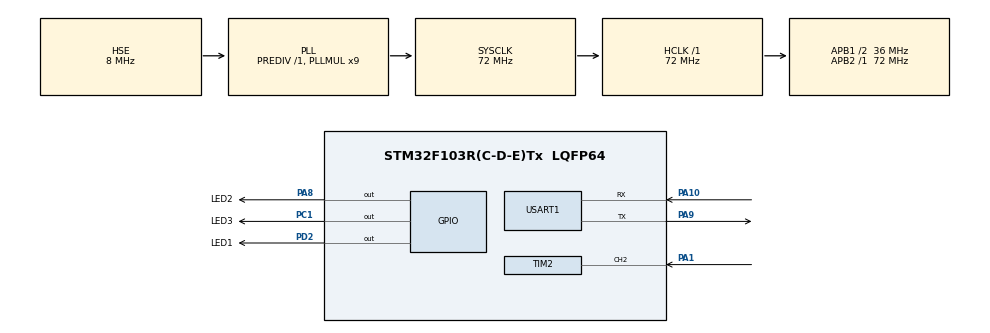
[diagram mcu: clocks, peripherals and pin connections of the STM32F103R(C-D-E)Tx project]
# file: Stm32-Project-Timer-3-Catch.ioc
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Mcu.Family=STM32F1
Mcu.Name=STM32F103R(C-D-E)Tx
Mcu.Package=LQFP64
NVIC.PriorityGroup=NVIC_PRIORITYGROUP_4
NVIC.TIM2_IRQn=true\:3\:0\:true\:false\:true\:true\:true\:true
PA1.Signal=S_TIM2_CH2
PA10.Mode=Asynchronous
PA10.Signal=USART1_RX
PA13.Mode=Serial_Wire
PA13.Signal=SYS_JTMS-SWDIO
PA14.Mode=Serial_Wire
PA14.Signal=SYS_JTCK-SWCLK
PA8.GPIO_Label=LED2
PA8.GPIO_PuPd=GPIO_PULLUP
PA8.GPIO_Speed=GPIO_SPEED_FREQ_HIGH
PA8.PinState=GPIO_PIN_SET
PA8.Signal=GPIO_Output
PA9.Mode=Asynchronous
PA9.Signal=USART1_TX
PC1.GPIO_Label=LED3
PC1.GPIO_PuPd=GPIO_PULLUP
PC1.GPIO_Speed=GPIO_SPEED_FREQ_HIGH
PC1.PinState=GPIO_PIN_SET
PC1.Signal=GPIO_Output
PD0-OSC_IN.Mode=HSE-External-Oscillator
PD0-OSC_IN.Signal=RCC_OSC_IN
PD1-OSC_OUT.Mode=HSE-External-Oscillator
PD1-OSC_OUT.Signal=RCC_OSC_OUT
PD2.GPIO_Label=LED1
PD2.GPIO_PuPd=GPIO_PULLUP
PD2.GPIO_Speed=GPIO_SPEED_FREQ_HIGH
PD2.PinState=GPIO_PIN_SET
PD2.Signal=GPIO_Output
ProjectManager.HeapSize=0x200
ProjectManager.StackSize=0x400
ProjectManager.TargetToolchain=MDK-ARM V5.32
RCC.AHBFreq_Value=72000000
RCC.APB1CLKDivider=RCC_HCLK_DIV2
RCC.APB1Freq_Value=36000000
RCC.APB1TimFreq_Value=72000000
RCC.APB2Freq_Value=72000000
RCC.APB2TimFreq_Value=72000000
RCC.HCLKFreq_Value=72000000
RCC.PLLMUL=RCC_PLL_MUL9
RCC.PLLSourceVirtual=RCC_PLLSOURCE_HSE
RCC.SYSCLKFreq_VALUE=72000000
RCC.SYSCLKSource=RCC_SYSCLKSOURCE_PLLCLK
RCC.USBFreq_Value=72000000
SH.S_TIM2_CH2.0=TIM2_CH2,Input_Capture2_from_TI2
TIM2.AutoReloadPreload=TIM_AUTORELOAD_PRELOAD_ENABLE
TIM2.Channel-Input_Capture2_from_TI2=TIM_CHANNEL_2
TIM2.Period=4999
TIM2.Prescaler=71
TIM7.Prescaler=71
USART1.VirtualMode=VM_ASYNC
VP_TIM7_VS_ClockSourceINT.Mode=Enable_Timer
board=custom

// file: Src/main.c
/* USER CODE BEGIN Header */
/**
  ******************************************************************************
  * @file           : main.c
  * @brief          : Main program body
  ******************************************************************************
  * @attention
  *
  * Copyright (c) 2023 STMicroelectronics.
  * All rights reserved.
  *
  * This software is licensed under terms that can be found in the LICENSE file
  * in the root directory of this software component.
  * If no LICENSE file comes with this software, it is provided AS-IS.
  *
  ******************************************************************************
  */
/* USER CODE END Header */
#include "main.h"
#include "tim.h"
#include "usart.h"
#include "gpio.h"

/* USER CODE BEGIN Includes */
#include"stdio.h"
/* USER CODE END Includes */

void SystemClock_Config(void);

//报错：观看重构printf函数
//int fputc(int ch,FILE *f)
//{
//	HAL_UART_Transmit(&huart1,(uint8_t *) &ch,1,0xfff);
//}
int main(void)
{

  /* MCU Configuration--------------------------------------------------------*/

  /* Reset of all peripherals, Initializes the Flash interface and the Systick. */
  HAL_Init();

  /* Configure the system clock */
  SystemClock_Config();

  /* Initialize all configured peripherals */
  MX_GPIO_Init();
  MX_TIM7_Init();
  MX_TIM2_Init();
  MX_USART1_UART_Init();
  /* USER CODE BEGIN 2 */
	printf("HELLO\r\n");
	HAL_TIM_Base_Start_IT(&htim2);			  /*开启定时器2溢出中断*/
	HAL_TIM_IC_Start_IT(&htim2,TIM_CHANNEL_2);/*开启定时器2通道2输入捕获中断*/
  /* USER CODE END 2 */

  /* Infinite loop */
  /* USER CODE BEGIN WHILE */
  while (1)
  {
	HAL_GPIO_WritePin(LED3_GPIO_Port, LED3_Pin, GPIO_PIN_SET);
	HAL_GPIO_WritePin(LED2_GPIO_Port, LED2_Pin, GPIO_PIN_SET);
	HAL_GPIO_WritePin(LED1_GPIO_Port, LED1_Pin, GPIO_PIN_SET);
	HAL_Delay(500);
	HAL_GPIO_WritePin(LED3_GPIO_Port, LED3_Pin, GPIO_PIN_RESET);
	HAL_GPIO_WritePin(LED2_GPIO_Port, LED2_Pin, GPIO_PIN_RESET);
	HAL_GPIO_WritePin(LED1_GPIO_Port, LED1_Pin, GPIO_PIN_RESET);
	HAL_Delay(100);
    /* USER CODE END WHILE */

  }
}

void SystemClock_Config(void)
{
  RCC_OscInitTypeDef RCC_OscInitStruct = {0};
  RCC_ClkInitTypeDef RCC_ClkInitStruct = {0};

  /** Initializes the RCC Oscillators according to the specified parameters
  * in the RCC_OscInitTypeDef structure.
  */
  RCC_OscInitStruct.OscillatorType = RCC_OSCILLATORTYPE_HSE;
  RCC_OscInitStruct.HSEState = RCC_HSE_ON;
  RCC_OscInitStruct.HSEPredivValue = RCC_HSE_PREDIV_DIV1;
  RCC_OscInitStruct.HSIState = RCC_HSI_ON;
  RCC_OscInitStruct.PLL.PLLState = RCC_PLL_ON;
  RCC_OscInitStruct.PLL.PLLSource = RCC_PLLSOURCE_HSE;
  RCC_OscInitStruct.PLL.PLLMUL = RCC_PLL_MUL9;
  if (HAL_RCC_OscConfig(&RCC_OscInitStruct) != HAL_OK)
  {
    Error_Handler();
  }

  /** Initializes the CPU, AHB and APB buses clocks
  */
  RCC_ClkInitStruct.ClockType = RCC_CLOCKTYPE_HCLK|RCC_CLOCKTYPE_SYSCLK
                              |RCC_CLOCKTYPE_PCLK1|RCC_CLOCKTYPE_PCLK2;
  RCC_ClkInitStruct.SYSCLKSource = RCC_SYSCLKSOURCE_PLLCLK;
  RCC_ClkInitStruct.AHBCLKDivider = RCC_SYSCLK_DIV1;
  RCC_ClkInitStruct.APB1CLKDivider = RCC_HCLK_DIV2;
  RCC_ClkInitStruct.APB2CLKDivider = RCC_HCLK_DIV1;

  if (HAL_RCC_ClockConfig(&RCC_ClkInitStruct, FLASH_LATENCY_2) != HAL_OK)
  {
    Error_Handler();
  }
}

void Error_Handler(void)
{
  __disable_irq();
  while (1)
  {
  }
}
